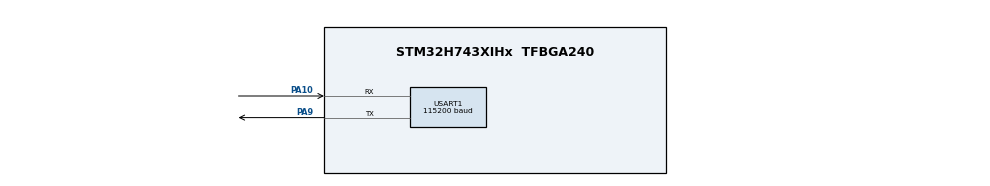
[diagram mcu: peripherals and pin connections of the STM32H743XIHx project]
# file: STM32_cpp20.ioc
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CORTEX_M7.default_mode_Activation=1
Dma.Request0=USART1_RX
Dma.Request1=USART1_TX
Dma.USART1_RX.0.Direction=DMA_PERIPH_TO_MEMORY
Dma.USART1_RX.0.EventEnable=DISABLE
Dma.USART1_RX.0.FIFOMode=DMA_FIFOMODE_DISABLE
Dma.USART1_RX.0.Instance=DMA1_Stream5
Dma.USART1_RX.0.MemDataAlignment=DMA_MDATAALIGN_BYTE
Dma.USART1_RX.0.MemInc=DMA_MINC_ENABLE
Dma.USART1_RX.0.Mode=DMA_NORMAL
Dma.USART1_RX.0.PeriphDataAlignment=DMA_PDATAALIGN_BYTE
Dma.USART1_RX.0.PeriphInc=DMA_PINC_DISABLE
Dma.USART1_RX.0.Polarity=HAL_DMAMUX_REQ_GEN_RISING
Dma.USART1_RX.0.Priority=DMA_PRIORITY_LOW
Dma.USART1_RX.0.RequestNumber=1
Dma.USART1_RX.0.SignalID=NONE
Dma.USART1_RX.0.SyncEnable=DISABLE
Dma.USART1_RX.0.SyncPolarity=HAL_DMAMUX_SYNC_NO_EVENT
Dma.USART1_RX.0.SyncRequestNumber=1
Dma.USART1_RX.0.SyncSignalID=NONE
Dma.USART1_TX.1.Direction=DMA_MEMORY_TO_PERIPH
Dma.USART1_TX.1.EventEnable=DISABLE
Dma.USART1_TX.1.FIFOMode=DMA_FIFOMODE_DISABLE
Dma.USART1_TX.1.Instance=DMA1_Stream4
Dma.USART1_TX.1.MemDataAlignment=DMA_MDATAALIGN_BYTE
Dma.USART1_TX.1.MemInc=DMA_MINC_ENABLE
Dma.USART1_TX.1.Mode=DMA_NORMAL
Dma.USART1_TX.1.PeriphDataAlignment=DMA_PDATAALIGN_BYTE
Dma.USART1_TX.1.PeriphInc=DMA_PINC_DISABLE
Dma.USART1_TX.1.Polarity=HAL_DMAMUX_REQ_GEN_RISING
Dma.USART1_TX.1.Priority=DMA_PRIORITY_LOW
Dma.USART1_TX.1.RequestNumber=1
Dma.USART1_TX.1.SignalID=NONE
Dma.USART1_TX.1.SyncEnable=DISABLE
Dma.USART1_TX.1.SyncPolarity=HAL_DMAMUX_SYNC_NO_EVENT
Dma.USART1_TX.1.SyncRequestNumber=1
Dma.USART1_TX.1.SyncSignalID=NONE
FREERTOS.Tasks01=defaultTask,24,128,StartDefaultTask,Default,NULL,Dynamic,NULL,NULL
FREERTOS.configENABLE_FPU=1
FREERTOS.configUSE_CO_ROUTINES=1
FREERTOS.configUSE_NEWLIB_REENTRANT=1
FREERTOS.configUSE_PREEMPTION=0
Mcu.Family=STM32H7
Mcu.Name=STM32H743XIHx
Mcu.Package=TFBGA240
NVIC.DMA1_Stream4_IRQn=true\:5\:0\:false\:false\:true\:false\:false\:true\:true
NVIC.DMA1_Stream5_IRQn=true\:5\:0\:false\:false\:true\:false\:false\:true\:true
NVIC.PriorityGroup=NVIC_PRIORITYGROUP_4
NVIC.TIM17_IRQn=true\:15\:0\:false\:false\:true\:false\:false\:true\:true
NVIC.TIM7_IRQn=true\:5\:0\:false\:false\:true\:true\:true\:true\:true
NVIC.TimeBase=TIM17_IRQn
NVIC.TimeBaseIP=TIM17
NVIC.USART1_IRQn=true\:5\:0\:false\:false\:true\:true\:true\:true\:true
PA10.Mode=Asynchronous
PA10.Signal=USART1_RX
PA9.Mode=Asynchronous
PA9.Signal=USART1_TX
PC14-OSC32_IN\ (OSC32_IN).Mode=LSE-External-Oscillator
PC14-OSC32_IN\ (OSC32_IN).Signal=RCC_OSC32_IN
PC15-OSC32_OUT\ (OSC32_OUT).Mode=LSE-External-Oscillator
PC15-OSC32_OUT\ (OSC32_OUT).Signal=RCC_OSC32_OUT
PH0-OSC_IN\ (PH0).Mode=HSE-External-Oscillator
PH0-OSC_IN\ (PH0).Signal=RCC_OSC_IN
PH1-OSC_OUT\ (PH1).Mode=HSE-External-Oscillator
PH1-OSC_OUT\ (PH1).Signal=RCC_OSC_OUT
ProjectManager.HeapSize=0x200
ProjectManager.StackSize=0x400
ProjectManager.TargetToolchain=CMake
RCC.ADCFreq_Value=2064000000
RCC.APB1Freq_Value=120000000
RCC.APB2Freq_Value=120000000
RCC.APB3Freq_Value=120000000
RCC.APB4Freq_Value=120000000
RCC.CortexFreq_Value=480000000
RCC.D1PPRE=RCC_APB3_DIV2
RCC.D2PPRE1=RCC_APB1_DIV2
RCC.D2PPRE2=RCC_APB2_DIV2
RCC.D3PPRE=RCC_APB4_DIV2
RCC.DIVM1=4
RCC.DIVM2=2
RCC.DIVN1=60
RCC.HCLKFreq_Value=240000000
RCC.HPRE=RCC_HCLK_DIV2
RCC.PLL2FRACN=0
RCC.PLL3FRACN=0
RCC.PLLFRACN=0
RCC.SYSCLKFreq_VALUE=480000000
RCC.SYSCLKSource=RCC_SYSCLKSOURCE_PLLCLK
RCC.USBFreq_Value=480000000
TIM7.AutoReloadPreload=TIM_AUTORELOAD_PRELOAD_ENABLE
TIM7.Period=19999
TIM7.Prescaler=59999
TIM7.TIM_MasterOutputTrigger=TIM_TRGO_RESET
USART1.BaudRate=115200
USART1.FIFOMode=FIFOMODE_ENABLE
USART1.RXFIFOThreshold=RXFIFO_THRESHOLD_HALFFULL
USART1.TXFIFOThreshold=TXFIFO_THRESHOLD_HALFFULL
USART1.VirtualMode-Asynchronous=VM_ASYNC
VP_FREERTOS_VS_CMSIS_V2.Mode=CMSIS_V2
VP_MBEDTLS_VS_MBEDTLS.Mode=Enabled
VP_MEMORYMAP_VS_MEMORYMAP.Mode=CurAppReg
VP_SYS_VS_tim17.Mode=TIM17
VP_TIM7_VS_ClockSourceINT.Mode=Enable_Timer
VP_TIM7_VS_OPM.Mode=OPM_bit
board=custom

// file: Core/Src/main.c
/* USER CODE BEGIN Header */
/**
 ******************************************************************************
 * @file           : main.c
 * @brief          : Main program body
 ******************************************************************************
 * @attention
 *
 * Copyright (c) 2025 STMicroelectronics.
 * All rights reserved.
 *
 * This software is licensed under terms that can be found in the LICENSE file
 * in the root directory of this software component.
 * If no LICENSE file comes with this software, it is provided AS-IS.
 *
 ******************************************************************************
 */
/* USER CODE END Header */
#include "main.h"
#include "cmsis_os.h"
#include "dma.h"
#include "mbedtls.h"
#include "tim.h"
#include "usart.h"
#include "gpio.h"

/* USER CODE BEGIN Includes */
#include <string.h>
#include <stdio.h>
#include <interrupt_simple_timer.h>
/* USER CODE END Includes */

void SystemClock_Config(void);
static void MPU_Config(void);
void MX_FREERTOS_Init(void);

/* USER CODE BEGIN 0 */

int _write(int file, char *ptr, int len)
{
  (void)file; // avoid unused parameter warning
  // Transmit data over UART1
  HAL_StatusTypeDef result = HAL_UART_Transmit(&huart1, (uint8_t *)ptr, len, HAL_MAX_DELAY);

  if (result != HAL_OK)
  {
    __BKPT(16); // Handle error if needed
    return -1;  // Indicate failure
  }

  return len;
}

/* USER CODE END 0 */

int main(void)
{

  /* MPU Configuration--------------------------------------------------------*/
  MPU_Config();

  /* MCU Configuration--------------------------------------------------------*/

  /* Reset of all peripherals, Initializes the Flash interface and the Systick. */
  HAL_Init();

  /* Configure the system clock */
  SystemClock_Config();

  /* Initialize all configured peripherals */
  MX_GPIO_Init();
  MX_DMA_Init();
  MX_USART1_UART_Init();
  MX_TIM7_Init();
  /* Call PreOsInit function */
  MX_MBEDTLS_Init();

  /* Init scheduler */
  osKernelInitialize();  /* Call init function for freertos objects (in cmsis_os2.c) */
  MX_FREERTOS_Init();

  /* Start scheduler */
  osKernelStart();

  /* We should never get here as control is now taken by the scheduler */

  /* Infinite loop */
  while (1)
  {

  }
}

void SystemClock_Config(void)
{
  RCC_OscInitTypeDef RCC_OscInitStruct = {0};
  RCC_ClkInitTypeDef RCC_ClkInitStruct = {0};

  /** Supply configuration update enable
  */
  HAL_PWREx_ConfigSupply(PWR_LDO_SUPPLY);

  /** Configure the main internal regulator output voltage
  */
  __HAL_PWR_VOLTAGESCALING_CONFIG(PWR_REGULATOR_VOLTAGE_SCALE0);

  while(!__HAL_PWR_GET_FLAG(PWR_FLAG_VOSRDY)) {}

  /** Initializes the RCC Oscillators according to the specified parameters
  * in the RCC_OscInitTypeDef structure.
  */
  RCC_OscInitStruct.OscillatorType = RCC_OSCILLATORTYPE_HSI;
  RCC_OscInitStruct.HSIState = RCC_HSI_DIV1;
  RCC_OscInitStruct.HSICalibrationValue = RCC_HSICALIBRATION_DEFAULT;
  RCC_OscInitStruct.PLL.PLLState = RCC_PLL_ON;
  RCC_OscInitStruct.PLL.PLLSource = RCC_PLLSOURCE_HSI;
  RCC_OscInitStruct.PLL.PLLM = 4;
  RCC_OscInitStruct.PLL.PLLN = 60;
  RCC_OscInitStruct.PLL.PLLP = 2;
  RCC_OscInitStruct.PLL.PLLQ = 2;
  RCC_OscInitStruct.PLL.PLLR = 2;
  RCC_OscInitStruct.PLL.PLLRGE = RCC_PLL1VCIRANGE_3;
  RCC_OscInitStruct.PLL.PLLVCOSEL = RCC_PLL1VCOWIDE;
  RCC_OscInitStruct.PLL.PLLFRACN = 0;
  if (HAL_RCC_OscConfig(&RCC_OscInitStruct) != HAL_OK)
  {
    Error_Handler();
  }

  /** Initializes the CPU, AHB and APB buses clocks
  */
  RCC_ClkInitStruct.ClockType = RCC_CLOCKTYPE_HCLK|RCC_CLOCKTYPE_SYSCLK
                              |RCC_CLOCKTYPE_PCLK1|RCC_CLOCKTYPE_PCLK2
                              |RCC_CLOCKTYPE_D3PCLK1|RCC_CLOCKTYPE_D1PCLK1;
  RCC_ClkInitStruct.SYSCLKSource = RCC_SYSCLKSOURCE_PLLCLK;
  RCC_ClkInitStruct.SYSCLKDivider = RCC_SYSCLK_DIV1;
  RCC_ClkInitStruct.AHBCLKDivider = RCC_HCLK_DIV2;
  RCC_ClkInitStruct.APB3CLKDivider = RCC_APB3_DIV2;
  RCC_ClkInitStruct.APB1CLKDivider = RCC_APB1_DIV2;
  RCC_ClkInitStruct.APB2CLKDivider = RCC_APB2_DIV2;
  RCC_ClkInitStruct.APB4CLKDivider = RCC_APB4_DIV2;

  if (HAL_RCC_ClockConfig(&RCC_ClkInitStruct, FLASH_LATENCY_4) != HAL_OK)
  {
    Error_Handler();
  }
}

 /* MPU Configuration */

void MPU_Config(void)
{
  MPU_Region_InitTypeDef MPU_InitStruct = {0};

  /* Disables the MPU */
  HAL_MPU_Disable();

  /** Initializes and configures the Region and the memory to be protected
  */
  MPU_InitStruct.Enable = MPU_REGION_ENABLE;
  MPU_InitStruct.Number = MPU_REGION_NUMBER0;
  MPU_InitStruct.BaseAddress = 0x0;
  MPU_InitStruct.Size = MPU_REGION_SIZE_4GB;
  MPU_InitStruct.SubRegionDisable = 0x87;
  MPU_InitStruct.TypeExtField = MPU_TEX_LEVEL0;
  MPU_InitStruct.AccessPermission = MPU_REGION_NO_ACCESS;
  MPU_InitStruct.DisableExec = MPU_INSTRUCTION_ACCESS_DISABLE;
  MPU_InitStruct.IsShareable = MPU_ACCESS_SHAREABLE;
  MPU_InitStruct.IsCacheable = MPU_ACCESS_NOT_CACHEABLE;
  MPU_InitStruct.IsBufferable = MPU_ACCESS_NOT_BUFFERABLE;

  HAL_MPU_ConfigRegion(&MPU_InitStruct);
  /* Enables the MPU */
  HAL_MPU_Enable(MPU_PRIVILEGED_DEFAULT);

}

void HAL_TIM_PeriodElapsedCallback(TIM_HandleTypeDef *htim)
{
  if (htim->Instance == TIM17)
  {
    HAL_IncTick();
  }
  /* USER CODE BEGIN Callback 1 */
  else if (htim->Instance == TIM7)
  {
    interrupt_simple_timer();
  }
  /* USER CODE END Callback 1 */
}

void Error_Handler(void)
{
  __disable_irq();
  while (1)
  {
  }
}

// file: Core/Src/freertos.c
/* USER CODE BEGIN Header */
/**
 ******************************************************************************
 * File Name          : freertos.c
 * Description        : Code for freertos applications
 ******************************************************************************
 * @attention
 *
 * Copyright (c) 2025 STMicroelectronics.
 * All rights reserved.
 *
 * This software is licensed under terms that can be found in the LICENSE file
 * in the root directory of this software component.
 * If no LICENSE file comes with this software, it is provided AS-IS.
 *
 ******************************************************************************
 */
/* USER CODE END Header */

#include "FreeRTOS.h"
#include "task.h"
#include "main.h"
#include "cmsis_os.h"

/* USER CODE BEGIN Includes */
#include "usart.h"
#include <stdio.h>
#include "uart_task.h"
/* USER CODE END Includes */

/* USER CODE BEGIN Variables */
static osThreadId_t uartTaskHandle;
static const osThreadAttr_t uartTask_attributes = {
    .name = "uartTask",
    .priority = (osPriority_t)osPriorityNormal,
    .stack_size = 128 * 8};

// ===== TASK FUNCTION =====
void StartUartTask(void *argument)
{
  (void)argument;
  float dummy_float = 0.0f;
  for (;;)
  {
    printf("Hello from STM32 %f\n", dummy_float);
    osDelay(10000); // 10000 ms = 10sec
    dummy_float += 1.01f;
  }
}

/* USER CODE END Variables */
/* Definitions for defaultTask */
osThreadId_t defaultTaskHandle;
const osThreadAttr_t defaultTask_attributes = {
  .name = "defaultTask",
  .stack_size = 128 * 4,
  .priority = (osPriority_t) osPriorityNormal,
};

void StartDefaultTask(void *argument);

void MX_FREERTOS_Init(void); /* (MISRA C 2004 rule 8.1) */

void MX_FREERTOS_Init(void) {
  /* USER CODE BEGIN Init */
  uart_task_init();
  uartTaskHandle = osThreadNew(StartUartTask, NULL, &uartTask_attributes);

  /* USER CODE END Init */

  /* Create the thread(s) */
  /* creation of defaultTask */
  defaultTaskHandle = osThreadNew(StartDefaultTask, NULL, &defaultTask_attributes);

}

void StartDefaultTask(void *argument)
{
  /* USER CODE BEGIN StartDefaultTask */
  (void)argument;
  /* Infinite loop */
  for (;;)
  {
    osDelay(1);
  }
  /* USER CODE END StartDefaultTask */
}
